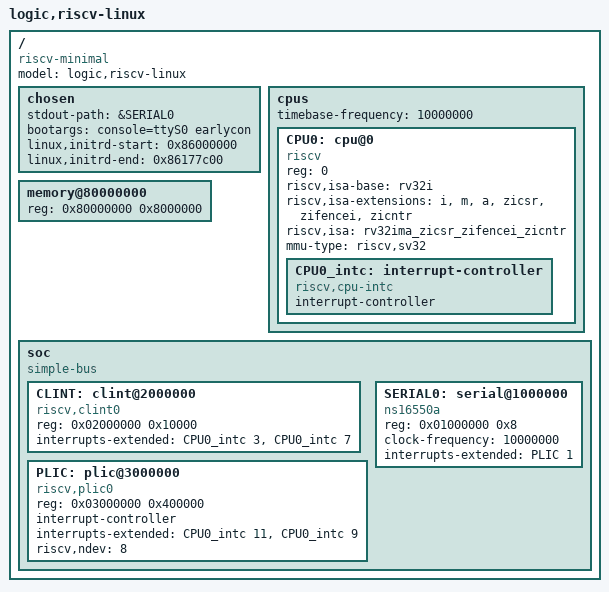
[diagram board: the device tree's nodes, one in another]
// the riscv_linux example: one rv32ima hart with sv32, a clint, a plic and
// an ns16550a uart. from the device tree of riscv-simulator (smode branch,
// github.com/uwrk9amtdn/riscv-simulator), with the initrd in /chosen and the
// clint and plic windows of the logic parts. build: dtc -O dtb -o soc.dtb soc.dts
//
// memory: fw_jump.bin (opensbi) at 0x80000000, Image (linux) at 0x80400000,
// rootfs.cpio at 0x86000000, this tree at 0x87000000 (a1 at reset)

/dts-v1/;

/ {
    #address-cells = <1>;
    #size-cells = <1>;

    compatible = "riscv-minimal";
    model = "logic,riscv-linux";

    chosen {
        stdout-path = &SERIAL0;
        bootargs = "console=ttyS0 earlycon";
        linux,initrd-start = <0x86000000>;
        linux,initrd-end = <0x86177c00>;
    };

    cpus {
        #address-cells = <1>;
        #size-cells = <0>;
        timebase-frequency = <10000000>; // mtime and the time csr

        CPU0: cpu@0 {
            device_type = "cpu";
            reg = <0>;
            status = "okay";
            compatible = "riscv";
            riscv,isa-base = "rv32i";
            riscv,isa-extensions = "i", "m", "a", "zicsr", "zifencei", "zicntr";
            riscv,isa = "rv32ima_zicsr_zifencei_zicntr";
            mmu-type = "riscv,sv32";

            CPU0_intc: interrupt-controller {
                #interrupt-cells = <1>;
                interrupt-controller;
                compatible = "riscv,cpu-intc";
            };
        };
    };

    memory@80000000 {
        device_type = "memory";
        reg = <0x80000000 0x8000000>; // 128 MiB
    };

    soc {
        compatible = "simple-bus";
        #address-cells = <1>;
        #size-cells = <1>;
        ranges;

        CLINT: clint@2000000 {
            compatible = "riscv,clint0";
            reg = <0x02000000 0x10000>;
            interrupts-extended = <&CPU0_intc 3 &CPU0_intc 7>; // msip, mtip
        };

        PLIC: plic@3000000 {
            compatible = "riscv,plic0";
            reg = <0x03000000 0x400000>;
            #address-cells = <0>;
            #interrupt-cells = <1>;
            interrupt-controller;
            interrupts-extended = <&CPU0_intc 11 &CPU0_intc 9>; // meip, seip
            riscv,ndev = <8>;
        };

        SERIAL0: serial@1000000 {
            compatible = "ns16550a";
            reg = <0x01000000 0x8>;
            clock-frequency = <10000000>; // the uart's clock parameter
            interrupts-extended = <&PLIC 1>;
        };
    };
};
